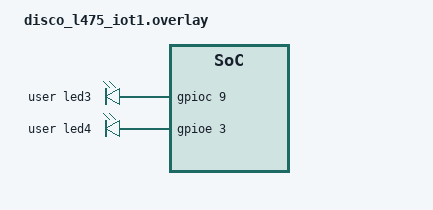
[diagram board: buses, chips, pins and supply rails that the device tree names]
/{
leds{
	compatible = "gpio-leds";
	led_3: led_3{
		gpios = <&gpioc 9 GPIO_ACTIVE_HIGH>;
		label = "user led3";
	};

	led_4: led_4{
		gpios = <&gpioe 3 GPIO_ACTIVE_HIGH>;
		label = "user led4";
	};
};

aliases{
		led3 = &led_3;
		led4 = &led_4;
		};

};
